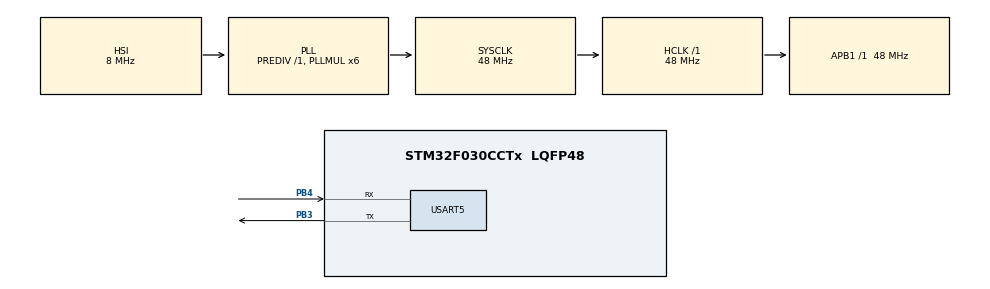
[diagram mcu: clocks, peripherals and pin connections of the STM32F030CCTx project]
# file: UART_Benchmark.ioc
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Mcu.Family=STM32F0
Mcu.Name=STM32F030CCTx
Mcu.Package=LQFP48
NVIC.USART3_6_IRQn=true\:0\:0\:false\:false\:true\:true\:true\:true
PB3.Mode=Asynchronous
PB3.Signal=USART5_TX
PB4.Mode=Asynchronous
PB4.Signal=USART5_RX
ProjectManager.HeapSize=0x200
ProjectManager.StackSize=0x400
ProjectManager.TargetToolchain=STM32CubeIDE
RCC.AHBFreq_Value=48000000
RCC.APB1Freq_Value=48000000
RCC.APB1TimFreq_Value=48000000
RCC.HCLKFreq_Value=48000000
RCC.PLLMUL=RCC_PLL_MUL6
RCC.SYSCLKFreq_VALUE=48000000
RCC.SYSCLKSource=RCC_SYSCLKSOURCE_PLLCLK
USART5.OverSampling=UART_OVERSAMPLING_16
USART5.VirtualMode-Asynchronous=VM_ASYNC
board=custom

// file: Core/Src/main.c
/* USER CODE BEGIN Header */
/**
  ******************************************************************************
  * @file           : main.c
  * @brief          : Main program body
  ******************************************************************************
  * @attention
  *
  * Copyright (c) 2024 STMicroelectronics.
  * All rights reserved.
  *
  * This software is licensed under terms that can be found in the LICENSE file
  * in the root directory of this software component.
  * If no LICENSE file comes with this software, it is provided AS-IS.
  *
  ******************************************************************************
  */
/* USER CODE END Header */
#include "main.h"

#include "uart_benchmark.h"

UART_HandleTypeDef huart5;

void SystemClock_Config(void);
static void MX_GPIO_Init(void);
static void MX_USART5_UART_Init(void);

int main(void)
{

    /* MCU Configuration--------------------------------------------------------*/

    /* Reset of all peripherals, Initializes the Flash interface and the Systick. */
    HAL_Init();

    /* Configure the system clock */
    SystemClock_Config();

    /* Initialize all configured peripherals */
    MX_GPIO_Init();
    MX_USART5_UART_Init();

    /* Infinite loop */
    while (1)
    {

        /* USER CODE BEGIN 3 */
        uart_benchmark();
    }
    /* USER CODE END 3 */
}

void SystemClock_Config(void)
{
    RCC_OscInitTypeDef RCC_OscInitStruct = {0};
    RCC_ClkInitTypeDef RCC_ClkInitStruct = {0};

    /** Initializes the RCC Oscillators according to the specified parameters
    * in the RCC_OscInitTypeDef structure.
    */
    RCC_OscInitStruct.OscillatorType = RCC_OSCILLATORTYPE_HSI;
    RCC_OscInitStruct.HSIState = RCC_HSI_ON;
    RCC_OscInitStruct.HSICalibrationValue = RCC_HSICALIBRATION_DEFAULT;
    RCC_OscInitStruct.PLL.PLLState = RCC_PLL_ON;
    RCC_OscInitStruct.PLL.PLLSource = RCC_PLLSOURCE_HSI;
    RCC_OscInitStruct.PLL.PLLMUL = RCC_PLL_MUL6;
    RCC_OscInitStruct.PLL.PREDIV = RCC_PREDIV_DIV1;
    if (HAL_RCC_OscConfig(&RCC_OscInitStruct) != HAL_OK)
    {
        Error_Handler();
    }

    /** Initializes the CPU, AHB and APB buses clocks
    */
    RCC_ClkInitStruct.ClockType = RCC_CLOCKTYPE_HCLK | RCC_CLOCKTYPE_SYSCLK
        | RCC_CLOCKTYPE_PCLK1;
    RCC_ClkInitStruct.SYSCLKSource = RCC_SYSCLKSOURCE_PLLCLK;
    RCC_ClkInitStruct.AHBCLKDivider = RCC_SYSCLK_DIV1;
    RCC_ClkInitStruct.APB1CLKDivider = RCC_HCLK_DIV1;

    if (HAL_RCC_ClockConfig(&RCC_ClkInitStruct, FLASH_LATENCY_1) != HAL_OK)
    {
        Error_Handler();
    }
}

static void MX_USART5_UART_Init(void)
{

    huart5.Instance = USART5;
    huart5.Init.BaudRate = 115200;
    huart5.Init.WordLength = UART_WORDLENGTH_8B;
    huart5.Init.StopBits = UART_STOPBITS_1;
    huart5.Init.Parity = UART_PARITY_NONE;
    huart5.Init.Mode = UART_MODE_TX_RX;
    huart5.Init.HwFlowCtl = UART_HWCONTROL_NONE;
    huart5.Init.OverSampling = UART_OVERSAMPLING_16;
    huart5.Init.OneBitSampling = UART_ONE_BIT_SAMPLE_DISABLE;
    huart5.AdvancedInit.AdvFeatureInit = UART_ADVFEATURE_NO_INIT;
    if (HAL_UART_Init(&huart5) != HAL_OK)
    {
        Error_Handler();
    }
}

static void MX_GPIO_Init(void)
{

    /* GPIO Ports Clock Enable */
    __HAL_RCC_GPIOB_CLK_ENABLE();

}

void Error_Handler(void)
{
    __disable_irq();
    while (1)
    {
    }
}
